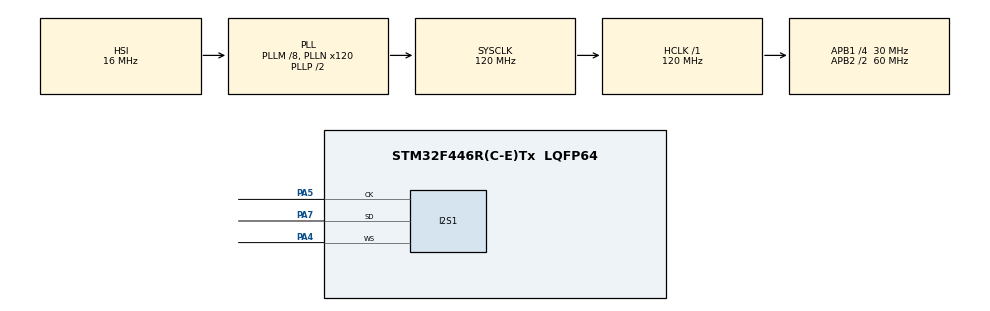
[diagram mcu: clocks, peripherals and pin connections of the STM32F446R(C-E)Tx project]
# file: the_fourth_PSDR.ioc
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Dma.Request0=SPI1_TX
Dma.SPI1_TX.0.Direction=DMA_MEMORY_TO_PERIPH
Dma.SPI1_TX.0.FIFOMode=DMA_FIFOMODE_DISABLE
Dma.SPI1_TX.0.Instance=DMA2_Stream3
Dma.SPI1_TX.0.MemDataAlignment=DMA_MDATAALIGN_HALFWORD
Dma.SPI1_TX.0.MemInc=DMA_MINC_ENABLE
Dma.SPI1_TX.0.Mode=DMA_CIRCULAR
Dma.SPI1_TX.0.PeriphDataAlignment=DMA_PDATAALIGN_HALFWORD
Dma.SPI1_TX.0.PeriphInc=DMA_PINC_DISABLE
Dma.SPI1_TX.0.Priority=DMA_PRIORITY_LOW
I2S1.AudioFreq=I2S_AUDIOFREQ_44K
I2S1.ErrorAudioFreq=-1.35 %
I2S1.FullDuplexMode=I2S_FULLDUPLEXMODE_DISABLE
I2S1.Instance=SPI$Index
I2S1.RealAudioFreq=43.402 KHz
I2S1.VirtualMode=I2S_MODE_MASTER
Mcu.Family=STM32F4
Mcu.Name=STM32F446R(C-E)Tx
Mcu.Package=LQFP64
NVIC.DMA2_Stream3_IRQn=true\:0\:0\:false\:false\:true\:false\:true\:true
NVIC.PriorityGroup=NVIC_PRIORITYGROUP_4
PA4.Mode=Half_Duplex_Master
PA4.Signal=I2S1_WS
PA5.Mode=Half_Duplex_Master
PA5.Signal=I2S1_CK
PA7.Mode=Half_Duplex_Master
PA7.Signal=I2S1_SD
ProjectManager.HeapSize=0x200
ProjectManager.StackSize=0x400
ProjectManager.TargetToolchain=STM32CubeIDE
RCC.AHBFreq_Value=120000000
RCC.APB1CLKDivider=RCC_HCLK_DIV4
RCC.APB1Freq_Value=30000000
RCC.APB1TimFreq_Value=60000000
RCC.APB2CLKDivider=RCC_HCLK_DIV2
RCC.APB2Freq_Value=60000000
RCC.APB2TimFreq_Value=120000000
RCC.CortexFreq_Value=120000000
RCC.HCLKFreq_Value=120000000
RCC.PLLI2SM=8
RCC.PLLI2SN=50
RCC.PLLM=8
RCC.PLLN=120
RCC.SYSCLKFreq_VALUE=120000000
RCC.SYSCLKSource=RCC_SYSCLKSOURCE_PLLCLK
RCC.USBFreq_Value=120000000
RCC.VCOOutputFreq_Value=240000000
board=custom

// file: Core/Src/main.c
/* USER CODE BEGIN Header */
/**
  ******************************************************************************
  * @file           : main.c
  * @brief          : Main program body
  ******************************************************************************
  * @attention
  *
  * Copyright (c) 2023 STMicroelectronics.
  * All rights reserved.
  *
  * This software is licensed under terms that can be found in the LICENSE file
  * in the root directory of this software component.
  * If no LICENSE file comes with this software, it is provided AS-IS.
  *
  ******************************************************************************
  */
/* USER CODE END Header */
#include "main.h"

/* USER CODE BEGIN Includes */
#include "math.h"
/* USER CODE END Includes */

/* USER CODE BEGIN PD */
#define SAMPLE_RATE 44000
#define BUFFER_SIZE 512
/* USER CODE END PD */

I2S_HandleTypeDef hi2s1;
DMA_HandleTypeDef hdma_spi1_tx;

/* USER CODE BEGIN PV */
uint16_t audio_buffer[BUFFER_SIZE];
/* USER CODE END PV */

void SystemClock_Config(void);
static void MX_GPIO_Init(void);
static void MX_DMA_Init(void);
static void MX_I2S1_Init(void);

/* USER CODE BEGIN 0 */
void generate_sine_wave(uint16_t* buffer, uint16_t size) {
    const double frequency = 500.0; // 1 kHz sine wave
    const double amplitude = 16384.0 / 4; // 16-bit signed amplitude

    for (int i = 0; i < size; ++i) {
        double t = (double)i / SAMPLE_RATE;
        double sine_value = amplitude * sin(2.0 * M_PI * frequency * t);
        buffer[i] = (uint16_t)(sine_value + amplitude);
    }
}
/* USER CODE END 0 */

int main(void)
{

  /* MCU Configuration--------------------------------------------------------*/

  /* Reset of all peripherals, Initializes the Flash interface and the Systick. */
  HAL_Init();

  /* Configure the system clock */
  SystemClock_Config();

  /* Initialize all configured peripherals */
  MX_GPIO_Init();
  MX_DMA_Init();
  MX_I2S1_Init();
  /* USER CODE BEGIN 2 */
  generate_sine_wave(audio_buffer, BUFFER_SIZE);
//  HAL_I2S_Transmit_DMA(&hi2s1, (uint16_t*)audio_buffer, BUFFER_SIZE);

  /* USER CODE END 2 */

  /* Infinite loop */
  /* USER CODE BEGIN WHILE */
  while (1)
  {
	  HAL_I2S_Transmit_DMA(&hi2s1, (uint16_t*)audio_buffer, BUFFER_SIZE);
	  HAL_Delay(500);
    /* USER CODE END WHILE */

  }
}

void SystemClock_Config(void)
{
  RCC_OscInitTypeDef RCC_OscInitStruct = {0};
  RCC_ClkInitTypeDef RCC_ClkInitStruct = {0};

  /** Configure the main internal regulator output voltage
  */
  __HAL_RCC_PWR_CLK_ENABLE();
  __HAL_PWR_VOLTAGESCALING_CONFIG(PWR_REGULATOR_VOLTAGE_SCALE3);

  /** Initializes the RCC Oscillators according to the specified parameters
  * in the RCC_OscInitTypeDef structure.
  */
  RCC_OscInitStruct.OscillatorType = RCC_OSCILLATORTYPE_HSI;
  RCC_OscInitStruct.HSIState = RCC_HSI_ON;
  RCC_OscInitStruct.HSICalibrationValue = RCC_HSICALIBRATION_DEFAULT;
  RCC_OscInitStruct.PLL.PLLState = RCC_PLL_ON;
  RCC_OscInitStruct.PLL.PLLSource = RCC_PLLSOURCE_HSI;
  RCC_OscInitStruct.PLL.PLLM = 8;
  RCC_OscInitStruct.PLL.PLLN = 120;
  RCC_OscInitStruct.PLL.PLLP = RCC_PLLP_DIV2;
  RCC_OscInitStruct.PLL.PLLQ = 2;
  RCC_OscInitStruct.PLL.PLLR = 2;
  if (HAL_RCC_OscConfig(&RCC_OscInitStruct) != HAL_OK)
  {
    Error_Handler();
  }

  /** Initializes the CPU, AHB and APB buses clocks
  */
  RCC_ClkInitStruct.ClockType = RCC_CLOCKTYPE_HCLK|RCC_CLOCKTYPE_SYSCLK
                              |RCC_CLOCKTYPE_PCLK1|RCC_CLOCKTYPE_PCLK2;
  RCC_ClkInitStruct.SYSCLKSource = RCC_SYSCLKSOURCE_PLLCLK;
  RCC_ClkInitStruct.AHBCLKDivider = RCC_SYSCLK_DIV1;
  RCC_ClkInitStruct.APB1CLKDivider = RCC_HCLK_DIV4;
  RCC_ClkInitStruct.APB2CLKDivider = RCC_HCLK_DIV2;

  if (HAL_RCC_ClockConfig(&RCC_ClkInitStruct, FLASH_LATENCY_3) != HAL_OK)
  {
    Error_Handler();
  }
}

static void MX_I2S1_Init(void)
{

  hi2s1.Instance = SPI1;
  hi2s1.Init.Mode = I2S_MODE_MASTER_TX;
  hi2s1.Init.Standard = I2S_STANDARD_PHILIPS;
  hi2s1.Init.DataFormat = I2S_DATAFORMAT_16B;
  hi2s1.Init.MCLKOutput = I2S_MCLKOUTPUT_DISABLE;
  hi2s1.Init.AudioFreq = I2S_AUDIOFREQ_44K;
  hi2s1.Init.CPOL = I2S_CPOL_LOW;
  hi2s1.Init.ClockSource = I2S_CLOCK_PLL;
  hi2s1.Init.FullDuplexMode = I2S_FULLDUPLEXMODE_DISABLE;
  if (HAL_I2S_Init(&hi2s1) != HAL_OK)
  {
    Error_Handler();
  }

}

static void MX_DMA_Init(void)
{

  /* DMA controller clock enable */
  __HAL_RCC_DMA2_CLK_ENABLE();

  /* DMA interrupt init */
  /* DMA2_Stream3_IRQn interrupt configuration */
  HAL_NVIC_SetPriority(DMA2_Stream3_IRQn, 0, 0);
  HAL_NVIC_EnableIRQ(DMA2_Stream3_IRQn);

}

static void MX_GPIO_Init(void)
{

  /* GPIO Ports Clock Enable */
  __HAL_RCC_GPIOA_CLK_ENABLE();

}

/* USER CODE BEGIN 4 */
void HAL_I2S_TxHalfCpltCallback(I2S_HandleTypeDef *hi2s) {
    generate_sine_wave(audio_buffer, BUFFER_SIZE);
}

void HAL_I2S_TxCpltCallback(I2S_HandleTypeDef *hi2s) {
    generate_sine_wave(&audio_buffer[BUFFER_SIZE / 2], BUFFER_SIZE / 2);
}
/* USER CODE END 4 */

void Error_Handler(void)
{
  __disable_irq();
  while (1)
  {
  }
}
